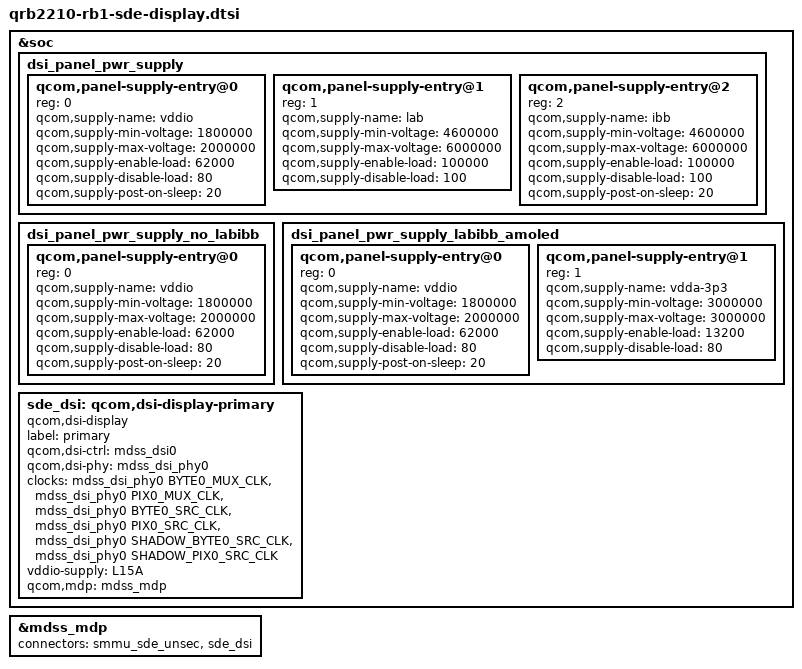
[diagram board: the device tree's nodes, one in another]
#include <dt-bindings/clock/mdss-14nm-pll-clk.h>
#include "dsi-panel-ext-bridge-1080p.dtsi"

&soc {
	dsi_panel_pwr_supply: dsi_panel_pwr_supply {
		#address-cells = <1>;
		#size-cells = <0>;

		qcom,panel-supply-entry@0 {
			reg = <0>;
			qcom,supply-name = "vddio";
			qcom,supply-min-voltage = <1800000>;
			qcom,supply-max-voltage = <2000000>;
			qcom,supply-enable-load = <62000>;
			qcom,supply-disable-load = <80>;
			qcom,supply-post-on-sleep = <20>;
		};

		qcom,panel-supply-entry@1 {
			reg = <1>;
			qcom,supply-name = "lab";
			qcom,supply-min-voltage = <4600000>;
			qcom,supply-max-voltage = <6000000>;
			qcom,supply-enable-load = <100000>;
			qcom,supply-disable-load = <100>;
		};

		qcom,panel-supply-entry@2 {
			reg = <2>;
			qcom,supply-name = "ibb";
			qcom,supply-min-voltage = <4600000>;
			qcom,supply-max-voltage = <6000000>;
			qcom,supply-enable-load = <100000>;
			qcom,supply-disable-load = <100>;
			qcom,supply-post-on-sleep = <20>;
		};
	};

	dsi_panel_pwr_supply_no_labibb: dsi_panel_pwr_supply_no_labibb {
		#address-cells = <1>;
		#size-cells = <0>;

		qcom,panel-supply-entry@0 {
			reg = <0>;
			qcom,supply-name = "vddio";
			qcom,supply-min-voltage = <1800000>;
			qcom,supply-max-voltage = <2000000>;
			qcom,supply-enable-load = <62000>;
			qcom,supply-disable-load = <80>;
			qcom,supply-post-on-sleep = <20>;
		};
	};

	dsi_panel_pwr_supply_labibb_amoled: dsi_panel_pwr_supply_labibb_amoled {
		#address-cells = <1>;
		#size-cells = <0>;

		qcom,panel-supply-entry@0 {
			reg = <0>;
			qcom,supply-name = "vddio";
			qcom,supply-min-voltage = <1800000>;
			qcom,supply-max-voltage = <2000000>;
			qcom,supply-enable-load = <62000>;
			qcom,supply-disable-load = <80>;
			qcom,supply-post-on-sleep = <20>;
		};

		qcom,panel-supply-entry@1 {
			reg = <1>;
			qcom,supply-name = "vdda-3p3";
			qcom,supply-min-voltage = <3000000>;
			qcom,supply-max-voltage = <3000000>;
			qcom,supply-enable-load = <13200>;
			qcom,supply-disable-load = <80>;
		};
	};

	sde_dsi: qcom,dsi-display-primary {
		compatible = "qcom,dsi-display";
		label = "primary";
		qcom,dsi-ctrl = <&mdss_dsi0>;
		qcom,dsi-phy = <&mdss_dsi_phy0>;

		clocks = <&mdss_dsi_phy0 BYTE0_MUX_CLK>,
			 <&mdss_dsi_phy0 PIX0_MUX_CLK>,
			 <&mdss_dsi_phy0 BYTE0_SRC_CLK>,
			 <&mdss_dsi_phy0 PIX0_SRC_CLK>,
			 <&mdss_dsi_phy0 SHADOW_BYTE0_SRC_CLK>,
			 <&mdss_dsi_phy0 SHADOW_PIX0_SRC_CLK>;
		clock-names = "mux_byte_clk0", "mux_pixel_clk0",
			"src_byte_clk0", "src_pixel_clk0",
			"shadow_byte_clk0", "shadow_pixel_clk0";

		vddio-supply = <&L15A>;
		qcom,mdp = <&mdss_mdp>;
	};
};

&mdss_mdp {
	  connectors = <&smmu_sde_unsec &sde_dsi>;
};
